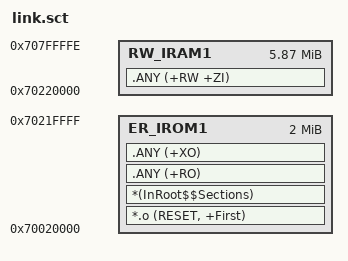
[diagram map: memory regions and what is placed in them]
; *************************************************************
; *** Scatter-Loading Description File generated by uVision ***
; *************************************************************

LR_IROM1 0x70020000 0x00200000  {    ; load region size_region
  ER_IROM1 0x70020000 0x00200000  {  ; load address = execution address
   *.o (RESET, +First)
   *(InRoot$$Sections)
   .ANY (+RO)
   .ANY (+XO)
  }
  RW_IRAM1 0x70220000 0x005DFFFF  {  ; RW data
   .ANY (+RW +ZI)
  }
}

